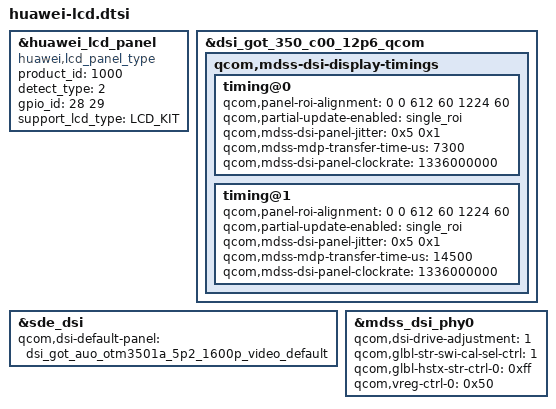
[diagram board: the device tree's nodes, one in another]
#include "../../../lcdkit3.0/got/devkit_lcd_kit.dtsi"
&huawei_lcd_panel {
	compatible = "huawei,lcd_panel_type";
	/* auto_key_info @ name: product_id type: uint32 default: 0 */
	product_id = <1000>;
	detect_type = <2>;
	/* auto_key_info @ name: gpio_id[2] type: int default: 0 */
	gpio_id = <28 29>;
	support_lcd_type = "LCD_KIT";
};

&dsi_got_350_c00_12p6_qcom {
	qcom,mdss-dsi-display-timings {
		timing@0 {
			qcom,panel-roi-alignment = <0 0 612 60 1224 60>;
			qcom,partial-update-enabled = "single_roi";
			qcom,mdss-dsi-panel-jitter = <0x5 0x1>;
                        qcom,mdss-mdp-transfer-time-us = <7300>;
                        qcom,mdss-dsi-panel-clockrate = <1336000000>;
		};
		timing@1 {
			qcom,panel-roi-alignment = <0 0 612 60 1224 60>;
			qcom,partial-update-enabled = "single_roi";
			qcom,mdss-dsi-panel-jitter = <0x5 0x1>;
                        qcom,mdss-mdp-transfer-time-us = <14500>;
                        qcom,mdss-dsi-panel-clockrate = <1336000000>;
		};
	};
};

&sde_dsi {
	qcom,dsi-default-panel = <&dsi_got_auo_otm3501a_5p2_1600p_video_default>;
};

&mdss_dsi_phy0 {
	qcom,dsi-drive-adjustment = <1>;
	qcom,glbl-str-swi-cal-sel-ctrl = <1>;
	qcom,glbl-hstx-str-ctrl-0 = <0xff>;
	qcom,vreg-ctrl-0 = <0x50>;
};

